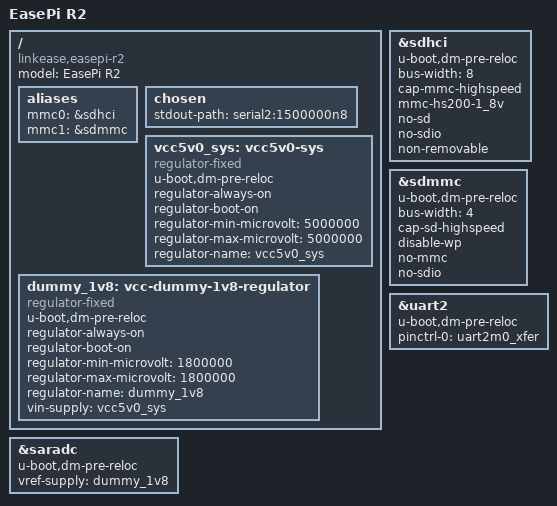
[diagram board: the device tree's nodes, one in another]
// SPDX-License-Identifier: (GPL-2.0+ OR MIT)

/dts-v1/;

#include "rk3588.dtsi"
#include "rk3588-u-boot.dtsi"
#include <dt-bindings/gpio/gpio.h>
#include <dt-bindings/input/input.h>
#include <dt-bindings/pinctrl/rockchip.h>

/ {
	model = "EasePi R2";
	compatible = "linkease,easepi-r2", "rockchip,rk3588";

	aliases {
		mmc0 = &sdhci;
		mmc1 = &sdmmc;
	};

	chosen {
		stdout-path = "serial2:1500000n8";
	};

	vcc5v0_sys: vcc5v0-sys {
		u-boot,dm-pre-reloc;
		compatible = "regulator-fixed";
		regulator-always-on;
		regulator-boot-on;
		regulator-min-microvolt = <5000000>;
		regulator-max-microvolt = <5000000>;
		regulator-name = "vcc5v0_sys";
	};

	dummy_1v8: vcc-dummy-1v8-regulator {
		u-boot,dm-pre-reloc;
		compatible = "regulator-fixed";
		regulator-always-on;
		regulator-boot-on;
		regulator-min-microvolt = <1800000>;
		regulator-max-microvolt = <1800000>;
		regulator-name = "dummy_1v8";
		vin-supply = <&vcc5v0_sys>;
	};
};

&saradc {
	u-boot,dm-pre-reloc;
	vref-supply = <&dummy_1v8>;
	status = "okay";
};

&sdhci {
	u-boot,dm-pre-reloc;
	bus-width = <8>;
	cap-mmc-highspeed;
	mmc-hs200-1_8v;
	no-sd;
	no-sdio;
	non-removable;
	status = "okay";
};

&sdmmc {
	u-boot,dm-pre-reloc;
	bus-width = <4>;
	cap-sd-highspeed;
	disable-wp;
	no-mmc;
	no-sdio;
	status = "okay";
};

&uart2 {
	u-boot,dm-pre-reloc;
	pinctrl-0 = <&uart2m0_xfer>;
	status = "okay";
};
